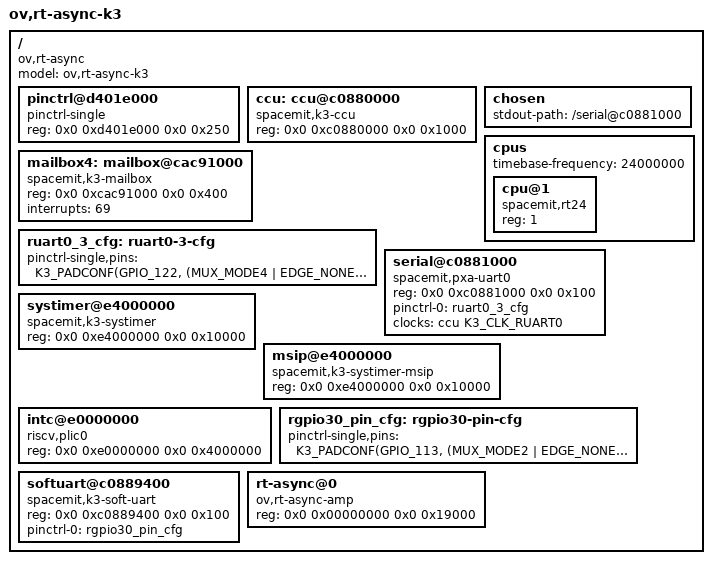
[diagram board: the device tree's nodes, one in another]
// SPDX-License-Identifier: MIT
//
// K3 RT24 rcpu1 设备树（内嵌进 rt-async ELF）
//
// U-Boot 对 RT24 **不做任何 DTB handoff**（k3-rproc.c 只 memcpy ELF 的
// PT_LOAD 段，不传 DTB 指针、不扫 FDT magic）。故本 DTB 经 `include_bytes!`
// 内嵌进 rcpu1 固件 ELF 的 .rodata 段，`Board::init` 直接 `init_dtb(...)`。
//
// 本 DTB 只描述 **rcpu1（hart 1）视角**：rcpu0（官方 esos）在另一 ELF 里，
// 两者由 U-Boot 从同一 itb 的 rcpu0-fw / rcpu1-fw 节点分别加载。
//
// 地址均为 rcpu1 物理视图（与 AP 共享同一物理地址空间，无别名）：
//   - SysTimer 0xe4000000：mtime(+0xbff8，全局)/mtimecmp(+0x4000+hart<<27)/
//     MSIP(+0x0+hart<<27，已上板实测)
//   - PLIC  0xe0000000：自定义布局，stride hart<<27
//   - UART0 0xc0881000：PXA 派生，IRQ 17（时钟链由 CCU driver 经 clocks
//     属性在 probe 前自动配置，pinmux 由 pinctrl-single driver 在 probe
//     前自动应用；SPL 握手见 handshake 模块）
//
// 编译链：cc -E（展开 #include/#define 宏）→ dtc（求值算术，生成 .dtb）。
// 宏定义见 k3-pinctrl.h（与 esos 互用）+ k3-clock.h（时钟 ID）。

/dts-v1/;

#include "k3-pinctrl.h"
#include "k3-clock.h"

/ {
	#address-cells = <2>;
	#size-cells = <2>;
	model = "ov,rt-async-k3";
	compatible = "ov,rt-async";

	// pinctrl-single 控制器（必须排在 serial 之前：DFS 先序保证
	// pinctrl driver 先 probe 并注册进 PINCTRL slot，之后 serial 节点
	// 在 probe 前自动应用 pinctrl-0 引脚配置）。
	pinctrl@d401e000 {
		compatible = "pinctrl-single";
		reg = <0x0 0xd401e000 0x0 0x250>;
	};

	// CCU 时钟控制器（DFS 先序：排在所有需时钟的外设之前，保证 CCU
	// driver 先 probe 注册进 CLOCK slot）。#clock-cells=<1> 表示 clocks
	// 属性里 phandle 后跟 1 个 ID cell（K3_CLK_xxx）。
		ccu: ccu@c0880000 {
			compatible = "spacemit,k3-ccu";
			reg = <0x0 0xc0880000 0x0 0x1000>;
			#clock-cells = <1>;
		};

		// 核间信令 mailbox（纯门铃模式，数据走共享内存 ov-rpc）。
		// mailbox4（starryos ↔ rcpu1）：基址 0xCAC91000，IRQ 69。
		//   必须用 mailbox4 而非 mailbox3——实测 rcpu0 DTB（k3_rt240_com260_ifx.dtb）
		//   中 mailbox3 = status "okay"（esos 正在使用），mailbox4 = status "disabled"
		//   （空闲）。若用 mailbox3，esos 的 rproc 活动与本核 ISR 竞争同一 FIFO，
		//   一方排空后另一方 NEW_MSG latch 永久卡死 → 中断风暴。
		//   不加 rcpu-communicate 属性：rcpu_communicate=false →
		//   USER0=数组0（AP/starryos）/USER1=数组1（rcpu1/本核），
		//   与 AP 侧 rt_shm 硬编码一致。
		mailbox4: mailbox@cac91000 {
			compatible = "spacemit,k3-mailbox";
			reg = <0x0 0xcac91000 0x0 0x400>;
			interrupts = <69>;
		};

	chosen {
		stdout-path = "/serial@c0881000";
	};

	cpus {
		#address-cells = <1>;
		#size-cells = <0>;
		// K3 SysTimer 频率 24MHz（esOS SOC_TIMER_FREQ）。
		// fdt_parser 用此推导 timebase；ClintK3 driver 也读它作 freq。
		timebase-frequency = <24000000>;

		cpu@1 {
			device_type = "cpu";
			// reg=<1> + 单 cpu 节点 → dtc 推导 boot_cpuid_phys=1，
			// driver probe 据此算 (mhartid<<27) per-hart 窗口。
			reg = <1>;
			compatible = "spacemit,rt24", "riscv";
		};
	};

	// R_UART0 引脚配置（原 clock.rs 硬编码的 ruart0_3_cfg：GPIO_122/123）。
	// K3_PADCONF 展开 → ((pinid)*4) (conf) 两组 cell，dtc 求值为
	// <0x1e8 0xd044 0x1ec 0xd044>（offset, value 对）。
	ruart0_3_cfg: ruart0-3-cfg {
		pinctrl-single,pins = <
			K3_PADCONF(GPIO_122, (MUX_MODE4 | EDGE_NONE | PULL_UP | PAD_DS8))  /* r_uart0_tx */
			K3_PADCONF(GPIO_123, (MUX_MODE4 | EDGE_NONE | PULL_UP | PAD_DS8))  /* r_uart0_rx */
		>;
	};

	// R_UART0（PXA 派生）。时钟链（ruart_14 上游 gate + UART0 末端 gate）
	// 由 CCU driver 经 clocks 属性在 probe 前自动配置；pinmux 由
	// pinctrl-single driver 在 probe 前据 pinctrl-0 自动应用。
	//
	// ⚠️ 本节点必须始终排在其他 serial 节点之前（DFS 先序 → 首个 probe
	// 占 slot 0 → console 派生取 SERIALS 首项 = 本口）。
	//
	// ── 机器人控制也走本口（共口方案，2026-08-27 原理图定案）────────────
	// 载板（k3-com260_kit_v02 原理图）40 针排针上唯一完整可用的 R.UART
	// 就是本口：GPIO_122/123 经 1.8V→3.3V 电平转换到 40pin pin29(TX)/
	// pin32(RX)（网络名 GPIO01/GPIO07 = MMC2_DAT3/DAT2，与 M.2 WiFi SDIO
	// 共网——不插 WiFi 卡即独占）。底盘/机械臂与 console log 共线：
	// ESP32 按 AA 55 帧头重同步、ZP10S 只认 '#' 头，log 文本两者皆忽略；
	// RX 方向（pin32）只接 ESP32 遥测，单向干净。
	// 备选双口（槽空时经 M.2 插座脚引出，无需焊 SODIMM）：R.UART4
	// （TX=GPIO_80→PCIeA_WAKEn 多槽共线、RX=GPIO_81→PCIeA_CLKREQn
	// @M.2 A 槽；m3，GPIO4 bank 驱动 M.2 3.3V 信号故原生 3.3V）/ R.UART2
	// （RX=40pin pin19 现成，TX=GPIO_57→M.2 E-key BT_EN 焊线；1.8V 需转换）。R.UART3 双双证伪：GPIO_89 模组未引出、
	// GPIO_88 接 EFM8 电源 MCU SHUTDOWN_REQ（mux 会触关机时序，禁用）；
	// 排针「UART1」组（pin8/10）是 SEC UART1（安全域，RT24 不可用）。
	serial@c0881000 {
		compatible = "spacemit,pxa-uart0";
		reg = <0x0 0xc0881000 0x0 0x100>;
		pinctrl-names = "default";
		pinctrl-0 = <&ruart0_3_cfg>;
		clocks = <&ccu K3_CLK_RUART0>;
	};

	// SysTimer（mtime/mtimecmp）。compatible 用 K3 专属串，回退 riscv,clint0。
	systimer@e4000000 {
		compatible = "spacemit,k3-systimer", "riscv,clint0";
		reg = <0x0 0xe4000000 0x0 0x10000>;
	};

	// SysTimer MSIP（与 systimer 同 reg，单独节点以便 Ipi driver 独立 probe）。
	msip@e4000000 {
		compatible = "spacemit,k3-systimer-msip", "riscv,clint0-msip";
		reg = <0x0 0xe4000000 0x0 0x10000>;
	};

	// K3 PLIC（自定义布局，stride hart<<27，compatible 仍为 riscv,plic0）。
	intc@e0000000 {
		compatible = "riscv,plic0";
		reg = <0x0 0xe0000000 0x0 0x4000000>;
	};

	// ── 软串口 TX（机械臂 ZP10S 独立通道，2026-08-29）─────────────────
	// 输出线 GPIO_113 mux m2 = R.GPIO[30]（40pin pin40，网络 I2S0_SDOUT，
	// 经载板 U2405 电平转换出 3.3V；线径直连 ZP10S 控制板 RX）。位时序由
	// AON_TIMER1 counter1（0xc0889000，PLIC int_src[9]）比较中断重建，
	// 参数在 soft_uart.rs 内为常量——本节点只为 pinctrl 应用与 probe 生命周期。
	rgpio30_pin_cfg: rgpio30-pin-cfg {
		pinctrl-single,pins = <
			K3_PADCONF(GPIO_113, (MUX_MODE2 | EDGE_NONE | PULL_UP | PAD_DS8))  /* rgpio30 = soft uart tx */
		>;
	};

	softuart@c0889400 {
		compatible = "spacemit,k3-soft-uart";
		reg = <0x0 0xc0889400 0x0 0x100>;
		pinctrl-names = "default";
		pinctrl-0 = <&rgpio30_pin_cfg>;
	};

	// 跨核共享内存（与 AP 侧 rt-async-amp/reserved rt_shm 对齐：RCPU SRAM 起始
	// 0xc0800000，0x19000——AP 侧主域地址是物理真相源，本节点故意写 RP 侧
	// **RCPU 本地 SRAM 别名窗口**地址：0x0..0x80000 镜像 0xC080_0000（手册 6.2，
	// rtbench 实测本地端口冷读 101ns/行 vs 主域端口 708ns/行 = 7×，且绕开
	// M2F 桥与 AP 流量的端口仲裁）。ov-shm 的 ShmDriver probe 读本节点 reg
	// 得基址/大小。K3 通知后端是硬件 mailbox（setup_interrupts 注册）。
	//
	// 大小由 ov-channels SharedMemory::<3> 的实际 footprint 决定（勿缩）：
	//   busy@+0x0（1B）；+0x100 起 3×Channel，每 Channel = magic/version(4B) +
	//   RingBuffer<128> (128×256B 消息 + 索引) = 0x8200 → 总 footprint =
	//   0x100 + 3×0x8200 = 0x18700，取整 0x19000。
	//   （旧 16KB 窗口装不下：AP 内核 is_valid() 遍历到 ch1.magic@+0x8300 越出
	//   窗口落入未映射页 → Supervisor Page Fault，2026-08-14 实锤。）
	//
	// 物理位置在 SRAM 起始（主域视图 0xc0800000，别名视图 0x0）：
	// 0xc086c000+0x19000 会超出 SRAM 末端 0xc0880000 且吞掉 rcpu0 的 vring
	// 保留区。代价：本窗在启动头 ~1s 是**还在执行的 SPL 代码**（SPL text
	// 主域 0xc0801000 起），且 U-Boot board_late_init 的 k3_clear_sram() 在
	// RP 上线 ~1.5s 会 memset 整个 512KB —— 故 RP 侧所有窗口写入必须延迟到
	// 上线 3s 之后（见 shm_ping.rs），自愈重初始化作后备。
	rt-async@0 {
		compatible = "ov,rt-async-amp";
		reg = <0x0 0x00000000 0x0 0x19000>;
	};
};
